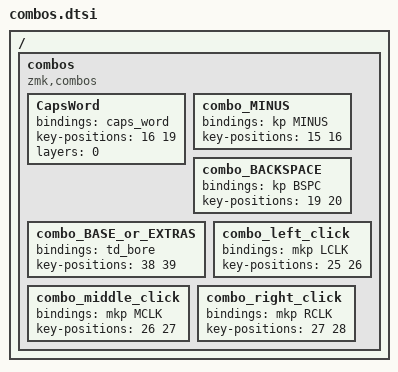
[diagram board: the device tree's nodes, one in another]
/ {
    combos {
        compatible = "zmk,combos";

        CapsWord {
            bindings = <&caps_word>;
            key-positions = <16 19>;
            layers = <0>;
        };

        combo_MINUS {
            bindings = <&kp MINUS>;
            key-positions = <15 16>;
        };

        combo_BACKSPACE {
            bindings = <&kp BSPC>;
            key-positions = <19 20>;
        };

        combo_BASE_or_EXTRAS {
            bindings = <&td_bore>;
            key-positions = <38 39>;
        };
        
        combo_left_click {
            bindings = <&mkp LCLK>;
            key-positions = <25 26>;
        };
        
        combo_middle_click {
            bindings = <&mkp MCLK>;
            key-positions = <26 27>;
        };

        combo_right_click {
            bindings = <&mkp RCLK>;
            key-positions = <27 28>;
        };
    };
};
